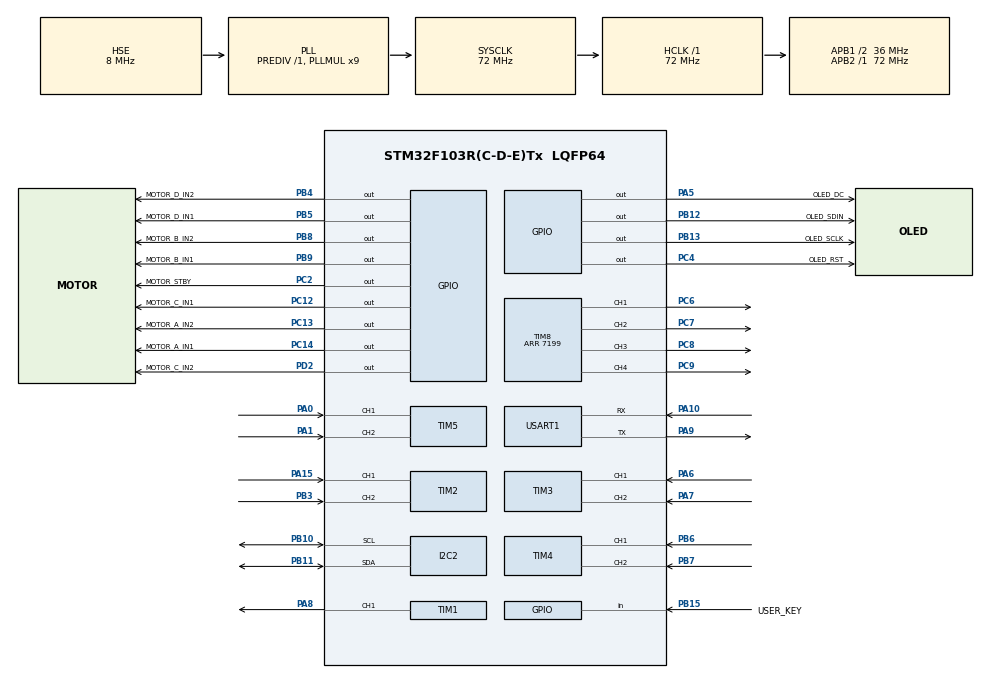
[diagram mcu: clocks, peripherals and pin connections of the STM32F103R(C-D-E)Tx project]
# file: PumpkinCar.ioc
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Dma.Request0=USART1_RX
Dma.Request1=USART1_TX
Dma.USART1_RX.0.Direction=DMA_PERIPH_TO_MEMORY
Dma.USART1_RX.0.Instance=DMA1_Channel5
Dma.USART1_RX.0.MemDataAlignment=DMA_MDATAALIGN_BYTE
Dma.USART1_RX.0.MemInc=DMA_MINC_ENABLE
Dma.USART1_RX.0.Mode=DMA_CIRCULAR
Dma.USART1_RX.0.PeriphDataAlignment=DMA_PDATAALIGN_BYTE
Dma.USART1_RX.0.PeriphInc=DMA_PINC_DISABLE
Dma.USART1_RX.0.Priority=DMA_PRIORITY_HIGH
Dma.USART1_TX.1.Direction=DMA_MEMORY_TO_PERIPH
Dma.USART1_TX.1.Instance=DMA1_Channel4
Dma.USART1_TX.1.MemDataAlignment=DMA_MDATAALIGN_BYTE
Dma.USART1_TX.1.MemInc=DMA_MINC_ENABLE
Dma.USART1_TX.1.Mode=DMA_NORMAL
Dma.USART1_TX.1.PeriphDataAlignment=DMA_PDATAALIGN_BYTE
Dma.USART1_TX.1.PeriphInc=DMA_PINC_DISABLE
Dma.USART1_TX.1.Priority=DMA_PRIORITY_LOW
FREERTOS.Tasks01=defaultTask,24,256,StartDefaultTask,Default,NULL,Dynamic,NULL,NULL;commTask,24,512,StartCommTask,Default,NULL,Dynamic,NULL,NULL;motorTask,32,512,StartMotorTask,Default,NULL,Dynamic,NULL,NULL;displayTask,8,512,StartDisplayTask,Default,NULL,Dynamic,NULL,NULL;imuTask,16,512,StartImuTask,Default,NULL,Dynamic,NULL,NULL
FREERTOS.configGENERATE_RUN_TIME_STATS=1
FREERTOS.configTOTAL_HEAP_SIZE=12288
FREERTOS.configUSE_PREEMPTION=1
Mcu.Family=STM32F1
Mcu.Name=STM32F103R(C-D-E)Tx
Mcu.Package=LQFP64
NVIC.DMA1_Channel4_IRQn=true\:5\:0\:false\:false\:true\:true\:false\:true\:true
NVIC.DMA1_Channel5_IRQn=true\:5\:0\:false\:false\:true\:true\:false\:true\:true
NVIC.PriorityGroup=NVIC_PRIORITYGROUP_4
NVIC.TIM6_IRQn=true\:15\:0\:false\:false\:true\:false\:false\:true\:true
NVIC.TimeBase=TIM6_IRQn
NVIC.TimeBaseIP=TIM6
NVIC.USART1_IRQn=true\:5\:0\:false\:false\:true\:true\:false\:true\:true
PA0-WKUP.Signal=S_TIM5_CH1
PA1.Signal=S_TIM5_CH2
PA10.Mode=Asynchronous
PA10.Signal=USART1_RX
PA13.Mode=Serial_Wire
PA13.Signal=SYS_JTMS-SWDIO
PA14.Mode=Serial_Wire
PA14.Signal=SYS_JTCK-SWCLK
PA15.Signal=S_TIM2_CH1_ETR
PA5.GPIO_Label=OLED_DC
PA5.Signal=GPIO_Output
PA6.Signal=S_TIM3_CH1
PA7.Signal=S_TIM3_CH2
PA8.Signal=S_TIM1_CH1
PA9.Mode=Asynchronous
PA9.Signal=USART1_TX
PB10.Mode=I2C
PB10.Signal=I2C2_SCL
PB11.Mode=I2C
PB11.Signal=I2C2_SDA
PB12.GPIO_Label=OLED_SDIN
PB12.Signal=GPIO_Output
PB13.GPIO_Label=OLED_SCLK
PB13.Signal=GPIO_Output
PB15.GPIO_Label=USER_KEY
PB15.GPIO_PuPd=GPIO_PULLUP
PB15.Signal=GPIO_Input
PB3.Signal=S_TIM2_CH2
PB4.GPIO_Label=MOTOR_D_IN2
PB4.Signal=GPIO_Output
PB5.GPIO_Label=MOTOR_D_IN1
PB5.Signal=GPIO_Output
PB6.Signal=S_TIM4_CH1
PB7.Signal=S_TIM4_CH2
PB8.GPIO_Label=MOTOR_B_IN2
PB8.Signal=GPIO_Output
PB9.GPIO_Label=MOTOR_B_IN1
PB9.Signal=GPIO_Output
PC12.GPIO_Label=MOTOR_C_IN1
PC12.Signal=GPIO_Output
PC13-TAMPER-RTC.GPIO_Label=MOTOR_A_IN2
PC13-TAMPER-RTC.Signal=GPIO_Output
PC14-OSC32_IN.GPIO_Label=MOTOR_A_IN1
PC14-OSC32_IN.Signal=GPIO_Output
PC2.GPIO_Label=MOTOR_STBY
PC2.Signal=GPIO_Output
PC4.GPIO_Label=OLED_RST
PC4.Signal=GPIO_Output
PC6.Signal=S_TIM8_CH1
PC7.Signal=S_TIM8_CH2
PC8.Signal=S_TIM8_CH3
PC9.Signal=S_TIM8_CH4
PD0-OSC_IN.Mode=HSE-External-Oscillator
PD0-OSC_IN.Signal=RCC_OSC_IN
PD1-OSC_OUT.Mode=HSE-External-Oscillator
PD1-OSC_OUT.Signal=RCC_OSC_OUT
PD2.GPIO_Label=MOTOR_C_IN2
PD2.Signal=GPIO_Output
ProjectManager.HeapSize=0x200
ProjectManager.StackSize=0x400
ProjectManager.TargetToolchain=CMake
RCC.AHBFreq_Value=72000000
RCC.APB1CLKDivider=RCC_HCLK_DIV2
RCC.APB1Freq_Value=36000000
RCC.APB1TimFreq_Value=72000000
RCC.APB2Freq_Value=72000000
RCC.APB2TimFreq_Value=72000000
RCC.HCLKFreq_Value=72000000
RCC.PLLMUL=RCC_PLL_MUL9
RCC.PLLSourceVirtual=RCC_PLLSOURCE_HSE
RCC.SYSCLKFreq_VALUE=72000000
RCC.SYSCLKSource=RCC_SYSCLKSOURCE_PLLCLK
RCC.USBFreq_Value=72000000
SH.S_TIM1_CH1.0=TIM1_CH1,PWM Generation1 CH1
SH.S_TIM2_CH1_ETR.0=TIM2_CH1,Encoder_Interface
SH.S_TIM2_CH2.0=TIM2_CH2,Encoder_Interface
SH.S_TIM3_CH1.0=TIM3_CH1,Encoder_Interface
SH.S_TIM3_CH2.0=TIM3_CH2,Encoder_Interface
SH.S_TIM4_CH1.0=TIM4_CH1,Encoder_Interface
SH.S_TIM4_CH2.0=TIM4_CH2,Encoder_Interface
SH.S_TIM5_CH1.0=TIM5_CH1,Encoder_Interface
SH.S_TIM5_CH2.0=TIM5_CH2,Encoder_Interface
SH.S_TIM8_CH1.0=TIM8_CH1,PWM Generation1 CH1
SH.S_TIM8_CH2.0=TIM8_CH2,PWM Generation2 CH2
SH.S_TIM8_CH3.0=TIM8_CH3,PWM Generation3 CH3
SH.S_TIM8_CH4.0=TIM8_CH4,PWM Generation4 CH4
TIM1.AutoReloadPreload=TIM_AUTORELOAD_PRELOAD_ENABLE
TIM1.Channel-PWM\ Generation1\ CH1=TIM_CHANNEL_1
TIM1.Period=19999
TIM1.Prescaler=71
TIM1.Pulse-PWM\ Generation1\ CH1=1500
TIM2.EncoderMode=TIM_ENCODERMODE_TI12
TIM2.IC1Filter=10
TIM2.IC2Filter=10
TIM3.EncoderMode=TIM_ENCODERMODE_TI12
TIM3.IC1Filter=10
TIM3.IC2Filter=10
TIM4.EncoderMode=TIM_ENCODERMODE_TI12
TIM4.IC1Filter=10
TIM4.IC2Filter=10
TIM5.EncoderMode=TIM_ENCODERMODE_TI12
TIM5.IC1Filter=10
TIM5.IC2Filter=10
TIM8.AutoReloadPreload=TIM_AUTORELOAD_PRELOAD_ENABLE
TIM8.Channel-PWM\ Generation1\ CH1=TIM_CHANNEL_1
TIM8.Channel-PWM\ Generation2\ CH2=TIM_CHANNEL_2
TIM8.Channel-PWM\ Generation3\ CH3=TIM_CHANNEL_3
TIM8.Channel-PWM\ Generation4\ CH4=TIM_CHANNEL_4
TIM8.Period=7199
USART1.VirtualMode=VM_ASYNC
VP_FREERTOS_VS_CMSIS_V2.Mode=CMSIS_V2
VP_SYS_VS_tim6.Mode=TIM6
VP_TIM1_VS_ClockSourceINT.Mode=Internal
board=custom

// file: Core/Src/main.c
/* USER CODE BEGIN Header */
/**
  ******************************************************************************
  * @file           : main.c
  * @brief          : Main program body
  ******************************************************************************
  * @attention
  *
  * Copyright (c) 2026 STMicroelectronics.
  * All rights reserved.
  *
  * This software is licensed under terms that can be found in the LICENSE file
  * in the root directory of this software component.
  * If no LICENSE file comes with this software, it is provided AS-IS.
  *
  ******************************************************************************
  */
/* USER CODE END Header */
#include "main.h"
#include "cmsis_os.h"
#include "dma.h"
#include "i2c.h"
#include "tim.h"
#include "usart.h"
#include "gpio.h"

void SystemClock_Config(void);
void MX_FREERTOS_Init(void);

int main(void)
{

  /* MCU Configuration--------------------------------------------------------*/

  /* Reset of all peripherals, Initializes the Flash interface and the Systick. */
  HAL_Init();

  /* Configure the system clock */
  SystemClock_Config();

  /* Initialize all configured peripherals */
  MX_GPIO_Init();
  MX_DMA_Init();
  MX_USART1_UART_Init();
  MX_TIM2_Init();
  MX_TIM3_Init();
  MX_TIM4_Init();
  MX_TIM8_Init();
  MX_TIM5_Init();
  MX_I2C2_Init();
  MX_TIM1_Init();

  /* Init scheduler */
  osKernelInitialize();  /* Call init function for freertos objects (in cmsis_os2.c) */
  MX_FREERTOS_Init();

  /* Start scheduler */
  osKernelStart();

  /* We should never get here as control is now taken by the scheduler */

  /* Infinite loop */
  while (1)
  {

  }
}

void SystemClock_Config(void)
{
  RCC_OscInitTypeDef RCC_OscInitStruct = {0};
  RCC_ClkInitTypeDef RCC_ClkInitStruct = {0};

  /** Initializes the RCC Oscillators according to the specified parameters
  * in the RCC_OscInitTypeDef structure.
  */
  RCC_OscInitStruct.OscillatorType = RCC_OSCILLATORTYPE_HSE;
  RCC_OscInitStruct.HSEState = RCC_HSE_ON;
  RCC_OscInitStruct.HSEPredivValue = RCC_HSE_PREDIV_DIV1;
  RCC_OscInitStruct.HSIState = RCC_HSI_ON;
  RCC_OscInitStruct.PLL.PLLState = RCC_PLL_ON;
  RCC_OscInitStruct.PLL.PLLSource = RCC_PLLSOURCE_HSE;
  RCC_OscInitStruct.PLL.PLLMUL = RCC_PLL_MUL9;
  if (HAL_RCC_OscConfig(&RCC_OscInitStruct) != HAL_OK)
  {
    Error_Handler();
  }

  /** Initializes the CPU, AHB and APB buses clocks
  */
  RCC_ClkInitStruct.ClockType = RCC_CLOCKTYPE_HCLK|RCC_CLOCKTYPE_SYSCLK
                              |RCC_CLOCKTYPE_PCLK1|RCC_CLOCKTYPE_PCLK2;
  RCC_ClkInitStruct.SYSCLKSource = RCC_SYSCLKSOURCE_PLLCLK;
  RCC_ClkInitStruct.AHBCLKDivider = RCC_SYSCLK_DIV1;
  RCC_ClkInitStruct.APB1CLKDivider = RCC_HCLK_DIV2;
  RCC_ClkInitStruct.APB2CLKDivider = RCC_HCLK_DIV1;

  if (HAL_RCC_ClockConfig(&RCC_ClkInitStruct, FLASH_LATENCY_2) != HAL_OK)
  {
    Error_Handler();
  }
}

void HAL_TIM_PeriodElapsedCallback(TIM_HandleTypeDef *htim)
{
  if (htim->Instance == TIM6)
  {
    HAL_IncTick();
  }
}

void Error_Handler(void)
{
  /* USER CODE BEGIN Error_Handler_Debug */
  HAL_GPIO_WritePin(MOTOR_STBY_GPIO_Port, MOTOR_STBY_Pin, GPIO_PIN_RESET);
  /* User can add his own implementation to report the HAL error return state */
  __disable_irq();
  while (1)
  {
  }
  /* USER CODE END Error_Handler_Debug */
}

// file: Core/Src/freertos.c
/* USER CODE BEGIN Header */
/**
  ******************************************************************************
  * File Name          : freertos.c
  * Description        : Code for freertos applications
  ******************************************************************************
  * @attention
  *
  * Copyright (c) 2026 STMicroelectronics.
  * All rights reserved.
  *
  * This software is licensed under terms that can be found in the LICENSE file
  * in the root directory of this software component.
  * If no LICENSE file comes with this software, it is provided AS-IS.
  *
  ******************************************************************************
  */
/* USER CODE END Header */

#include "FreeRTOS.h"
#include "task.h"
#include "main.h"
#include "cmsis_os.h"

/* USER CODE BEGIN Includes */
#include "comm_app.h"
#include "motor_app.h"
#include "display_app.h"
#include "imu_app.h"
/* USER CODE END Includes */

/* Definitions for defaultTask */
osThreadId_t defaultTaskHandle;
const osThreadAttr_t defaultTask_attributes = {
  .name = "defaultTask",
  .stack_size = 256 * 4,
  .priority = (osPriority_t) osPriorityNormal,
};
/* Definitions for commTask */
osThreadId_t commTaskHandle;
const osThreadAttr_t commTask_attributes = {
  .name = "commTask",
  .stack_size = 512 * 4,
  .priority = (osPriority_t) osPriorityNormal,
};
/* Definitions for motorTask */
osThreadId_t motorTaskHandle;
const osThreadAttr_t motorTask_attributes = {
  .name = "motorTask",
  .stack_size = 512 * 4,
  .priority = (osPriority_t) osPriorityAboveNormal,
};
/* Definitions for displayTask */
osThreadId_t displayTaskHandle;
const osThreadAttr_t displayTask_attributes = {
  .name = "displayTask",
  .stack_size = 512 * 4,
  .priority = (osPriority_t) osPriorityLow,
};
/* Definitions for imuTask */
osThreadId_t imuTaskHandle;
const osThreadAttr_t imuTask_attributes = {
  .name = "imuTask",
  .stack_size = 512 * 4,
  .priority = (osPriority_t) osPriorityBelowNormal,
};

void StartDefaultTask(void *argument);
void StartCommTask(void *argument);
void StartMotorTask(void *argument);
void StartDisplayTask(void *argument);
void StartImuTask(void *argument);

void MX_FREERTOS_Init(void); /* (MISRA C 2004 rule 8.1) */

/* Hook prototypes */
void configureTimerForRunTimeStats(void);
unsigned long getRunTimeCounterValue(void);

/* USER CODE BEGIN 1 */
/* Functions needed when configGENERATE_RUN_TIME_STATS is on */
__weak void configureTimerForRunTimeStats(void)
{

}

__weak unsigned long getRunTimeCounterValue(void)
{
return 0;
}
/* USER CODE END 1 */

void MX_FREERTOS_Init(void) {

  /* Create the thread(s) */
  /* creation of defaultTask */
  defaultTaskHandle = osThreadNew(StartDefaultTask, NULL, &defaultTask_attributes);

  /* creation of commTask */
  commTaskHandle = osThreadNew(StartCommTask, NULL, &commTask_attributes);

  /* creation of motorTask */
  motorTaskHandle = osThreadNew(StartMotorTask, NULL, &motorTask_attributes);

  /* creation of displayTask */
  displayTaskHandle = osThreadNew(StartDisplayTask, NULL, &displayTask_attributes);

  /* creation of imuTask */
  imuTaskHandle = osThreadNew(StartImuTask, NULL, &imuTask_attributes);

  /* USER CODE BEGIN RTOS_THREADS */
  if ((defaultTaskHandle == NULL) || (commTaskHandle == NULL) ||
      (motorTaskHandle == NULL) || (displayTaskHandle == NULL) || (imuTaskHandle == NULL))
  {
    Error_Handler();
  }
  /* add threads, ... */
  /* USER CODE END RTOS_THREADS */

}

void StartDefaultTask(void *argument)
{
  /* USER CODE BEGIN StartDefaultTask */
  for (;;)
  {
    osDelay(1U);
  }
  /* USER CODE END StartDefaultTask */
}

void StartCommTask(void *argument)
{
  /* USER CODE BEGIN StartCommTask */
  CommApp_Run();
  /* USER CODE END StartCommTask */
}

void StartMotorTask(void *argument)
{
  /* USER CODE BEGIN StartMotorTask */
  MotorApp_Run();
  /* USER CODE END StartMotorTask */
}

void StartDisplayTask(void *argument)
{
  /* USER CODE BEGIN StartDisplayTask */
  DisplayApp_Run();
  /* USER CODE END StartDisplayTask */
}

void StartImuTask(void *argument)
{
  /* USER CODE BEGIN StartImuTask */
  ImuApp_Run();
  /* USER CODE END StartImuTask */
}
